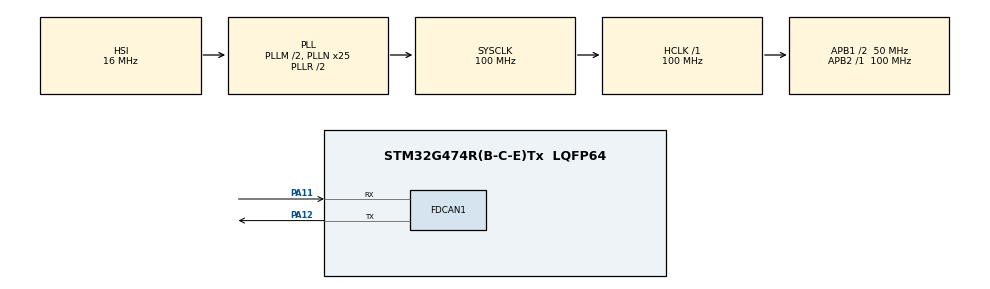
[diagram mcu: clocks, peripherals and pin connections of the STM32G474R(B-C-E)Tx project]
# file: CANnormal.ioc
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FDCAN1.AutoRetransmission=ENABLE
FDCAN1.CalculateBaudRateNominal=500000
FDCAN1.CalculateTimeBitNominal=2000
FDCAN1.CalculateTimeQuantumNominal=20.0
FDCAN1.DataPrescaler=5
FDCAN1.DataSyncJumpWidth=9
FDCAN1.DataTimeSeg1=10
FDCAN1.DataTimeSeg2=9
FDCAN1.FrameFormat=FDCAN_FRAME_FD_BRS
FDCAN1.NominalPrescaler=1
FDCAN1.NominalSyncJumpWidth=15
FDCAN1.NominalTimeSeg1=84
FDCAN1.NominalTimeSeg2=15
Mcu.Family=STM32G4
Mcu.Name=STM32G474R(B-C-E)Tx
Mcu.Package=LQFP64
NVIC.FDCAN1_IT0_IRQn=true\:0\:0\:false\:false\:true\:true\:true\:true
NVIC.PriorityGroup=NVIC_PRIORITYGROUP_4
PA11.Mode=FDCAN_Activate
PA11.Signal=FDCAN1_RX
PA12.Mode=FDCAN_Activate
PA12.Signal=FDCAN1_TX
ProjectManager.HeapSize=0x200
ProjectManager.StackSize=0x400
ProjectManager.TargetToolchain=STM32CubeIDE
RCC.ADC12Freq_Value=100000000
RCC.ADC345Freq_Value=100000000
RCC.AHBFreq_Value=100000000
RCC.APB1CLKDivider=RCC_HCLK_DIV2
RCC.APB1Freq_Value=50000000
RCC.APB1TimFreq_Value=100000000
RCC.APB2Freq_Value=100000000
RCC.APB2TimFreq_Value=100000000
RCC.CortexFreq_Value=100000000
RCC.EXTERNAL_CLOCK_VALUE=12288000
RCC.HCLKFreq_Value=100000000
RCC.HSE_VALUE=8000000
RCC.HSI48_VALUE=48000000
RCC.HSI_VALUE=16000000
RCC.LSE_VALUE=32768
RCC.PLLM=RCC_PLLM_DIV2
RCC.PLLN=25
RCC.SYSCLKFreq_VALUE=100000000
RCC.SYSCLKSource=RCC_SYSCLKSOURCE_PLLCLK
RCC.USBFreq_Value=100000000
RCC.VCOOutputFreq_Value=200000000
VP_SYS_VS_DBSignals.Mode=DisableDeadBatterySignals
board=custom

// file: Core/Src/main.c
/* USER CODE BEGIN Header */
/**
  ******************************************************************************
  * @file           : main.c
  * @brief          : Main program body
  ******************************************************************************
  * @attention
  *
  * Copyright (c) 2026 STMicroelectronics.
  * All rights reserved.
  *
  * This software is licensed under terms that can be found in the LICENSE file
  * in the root directory of this software component.
  * If no LICENSE file comes with this software, it is provided AS-IS.
  *
  ******************************************************************************
  */
/* USER CODE END Header */

#include "main.h"

FDCAN_HandleTypeDef hfdcan1;

/* USER CODE BEGIN PV */
FDCAN_TxHeaderTypeDef TxHeader;
FDCAN_RxHeaderTypeDef RxHeader;
uint8_t TxData[8] = {0x01, 0x02, 0x03, 0x04, 0x05, 0x06, 0x07, 0x08};
uint8_t RxData[8];
/* USER CODE END PV */

void SystemClock_Config(void);
static void MX_GPIO_Init(void);
static void MX_FDCAN1_Init(void);

int main(void)
{

  /* MCU Configuration--------------------------------------------------------*/

  /* Reset of all peripherals, Initializes the Flash interface and the Systick. */
  HAL_Init();

  /* Configure the system clock */
  SystemClock_Config();

  /* Initialize all configured peripherals */
  MX_GPIO_Init();
  MX_FDCAN1_Init();

  /* USER CODE BEGIN 2 */
  FDCAN_FilterTypeDef sFilterConfig;

  sFilterConfig.IdType       = FDCAN_STANDARD_ID;
  sFilterConfig.FilterIndex  = 0;
  sFilterConfig.FilterType   = FDCAN_FILTER_MASK;
  sFilterConfig.FilterConfig = FDCAN_FILTER_TO_RXFIFO0;
  sFilterConfig.FilterID1    = 0x000;
  sFilterConfig.FilterID2    = 0x000;

  if (HAL_FDCAN_ConfigFilter(&hfdcan1, &sFilterConfig) != HAL_OK)
  {
    Error_Handler();
  }

  if (HAL_FDCAN_ConfigGlobalFilter(&hfdcan1,
                                   FDCAN_REJECT,
                                   FDCAN_REJECT,
                                   FDCAN_FILTER_REMOTE,
                                   FDCAN_FILTER_REMOTE) != HAL_OK)
  {
    Error_Handler();
  }

  if (HAL_FDCAN_Start(&hfdcan1) != HAL_OK)
  {
    Error_Handler();
  }

  if (HAL_FDCAN_ActivateNotification(&hfdcan1, FDCAN_IT_RX_FIFO0_NEW_MESSAGE, 0) != HAL_OK)
  {
    Error_Handler();
  }
  /* USER CODE END 2 */

  /* Infinite loop */
  /* USER CODE BEGIN WHILE */
  while (1)
  {
    TxHeader.Identifier          = 0x11;
    TxHeader.IdType              = FDCAN_STANDARD_ID;
    TxHeader.TxFrameType         = FDCAN_DATA_FRAME;
    TxHeader.DataLength          = FDCAN_DLC_BYTES_8;
    TxHeader.ErrorStateIndicator = FDCAN_ESI_ACTIVE;
    TxHeader.BitRateSwitch       = FDCAN_BRS_OFF;
    TxHeader.FDFormat             = FDCAN_CLASSIC_CAN;
    TxHeader.TxEventFifoControl  = FDCAN_NO_TX_EVENTS;
    TxHeader.MessageMarker       = 0;

    if (HAL_FDCAN_AddMessageToTxFifoQ(&hfdcan1, &TxHeader, TxData) != HAL_OK)
    {
      Error_Handler();
    }

    HAL_Delay(500);
    /* USER CODE END WHILE */

  }
}

void SystemClock_Config(void)
{
  RCC_OscInitTypeDef RCC_OscInitStruct = {0};
  RCC_ClkInitTypeDef RCC_ClkInitStruct = {0};

  HAL_PWREx_ControlVoltageScaling(PWR_REGULATOR_VOLTAGE_SCALE1);

  RCC_OscInitStruct.OscillatorType      = RCC_OSCILLATORTYPE_HSI;
  RCC_OscInitStruct.HSIState            = RCC_HSI_ON;
  RCC_OscInitStruct.HSICalibrationValue = RCC_HSICALIBRATION_DEFAULT;
  RCC_OscInitStruct.PLL.PLLState        = RCC_PLL_ON;
  RCC_OscInitStruct.PLL.PLLSource       = RCC_PLLSOURCE_HSI;
  RCC_OscInitStruct.PLL.PLLM           = RCC_PLLM_DIV2;
  RCC_OscInitStruct.PLL.PLLN           = 25;
  RCC_OscInitStruct.PLL.PLLP           = RCC_PLLP_DIV2;
  RCC_OscInitStruct.PLL.PLLQ           = RCC_PLLQ_DIV2;
  RCC_OscInitStruct.PLL.PLLR           = RCC_PLLR_DIV2;
  if (HAL_RCC_OscConfig(&RCC_OscInitStruct) != HAL_OK)
  {
    Error_Handler();
  }

  RCC_ClkInitStruct.ClockType      = RCC_CLOCKTYPE_HCLK | RCC_CLOCKTYPE_SYSCLK
                                   | RCC_CLOCKTYPE_PCLK1 | RCC_CLOCKTYPE_PCLK2;
  RCC_ClkInitStruct.SYSCLKSource   = RCC_SYSCLKSOURCE_PLLCLK;
  RCC_ClkInitStruct.AHBCLKDivider  = RCC_SYSCLK_DIV1;
  RCC_ClkInitStruct.APB1CLKDivider = RCC_HCLK_DIV2;
  RCC_ClkInitStruct.APB2CLKDivider = RCC_HCLK_DIV1;

  if (HAL_RCC_ClockConfig(&RCC_ClkInitStruct, FLASH_LATENCY_3) != HAL_OK)
  {
    Error_Handler();
  }
}

static void MX_FDCAN1_Init(void)
{

  hfdcan1.Instance                   = FDCAN1;
  hfdcan1.Init.ClockDivider          = FDCAN_CLOCK_DIV1;
  hfdcan1.Init.FrameFormat           = FDCAN_FRAME_CLASSIC;
  hfdcan1.Init.Mode                  = FDCAN_MODE_NORMAL;
  hfdcan1.Init.AutoRetransmission    = ENABLE;
  hfdcan1.Init.TransmitPause         = DISABLE;
  hfdcan1.Init.ProtocolException     = DISABLE;
  hfdcan1.Init.NominalPrescaler      = 1;
  hfdcan1.Init.NominalSyncJumpWidth  = 15;
  hfdcan1.Init.NominalTimeSeg1       = 84;
  hfdcan1.Init.NominalTimeSeg2       = 15;
  hfdcan1.Init.DataPrescaler         = 5;
  hfdcan1.Init.DataSyncJumpWidth     = 9;
  hfdcan1.Init.DataTimeSeg1          = 10;
  hfdcan1.Init.DataTimeSeg2          = 9;
  hfdcan1.Init.StdFiltersNbr         = 1;
  hfdcan1.Init.ExtFiltersNbr         = 0;
  hfdcan1.Init.TxFifoQueueMode       = FDCAN_TX_FIFO_OPERATION;

  if (HAL_FDCAN_Init(&hfdcan1) != HAL_OK)
  {
    Error_Handler();
  }

}

static void MX_GPIO_Init(void)
{
  GPIO_InitTypeDef GPIO_InitStruct = {0};

  __HAL_RCC_GPIOA_CLK_ENABLE();

  GPIO_InitStruct.Pin       = GPIO_PIN_11 | GPIO_PIN_12;
  GPIO_InitStruct.Mode      = GPIO_MODE_AF_PP;
  GPIO_InitStruct.Pull      = GPIO_NOPULL;
  GPIO_InitStruct.Speed     = GPIO_SPEED_FREQ_HIGH;
  GPIO_InitStruct.Alternate = GPIO_AF9_FDCAN1;
  HAL_GPIO_Init(GPIOA, &GPIO_InitStruct);

  HAL_GPIO_WritePin(GPIOA, GPIO_PIN_5, GPIO_PIN_RESET);

  GPIO_InitStruct.Pin       = GPIO_PIN_5;
  GPIO_InitStruct.Mode      = GPIO_MODE_OUTPUT_PP;
  GPIO_InitStruct.Pull      = GPIO_NOPULL;
  GPIO_InitStruct.Speed     = GPIO_SPEED_FREQ_LOW;
  GPIO_InitStruct.Alternate = 0;
  HAL_GPIO_Init(GPIOA, &GPIO_InitStruct);

}

/* USER CODE BEGIN 4 */
void HAL_FDCAN_RxFifo0Callback(FDCAN_HandleTypeDef *hfdcan, uint32_t RxFifo0ITs)
{
  if ((RxFifo0ITs & FDCAN_IT_RX_FIFO0_NEW_MESSAGE) != RESET)
  {
    if (HAL_FDCAN_GetRxMessage(hfdcan, FDCAN_RX_FIFO0, &RxHeader, RxData) != HAL_OK)
    {
      Error_Handler();
    }

    HAL_GPIO_TogglePin(GPIOA, GPIO_PIN_5);

    if (HAL_FDCAN_ActivateNotification(hfdcan, FDCAN_IT_RX_FIFO0_NEW_MESSAGE, 0) != HAL_OK)
    {
      Error_Handler();
    }
  }
}
/* USER CODE END 4 */

void Error_Handler(void)
{
  __disable_irq();
  while (1)
  {
  }
}
